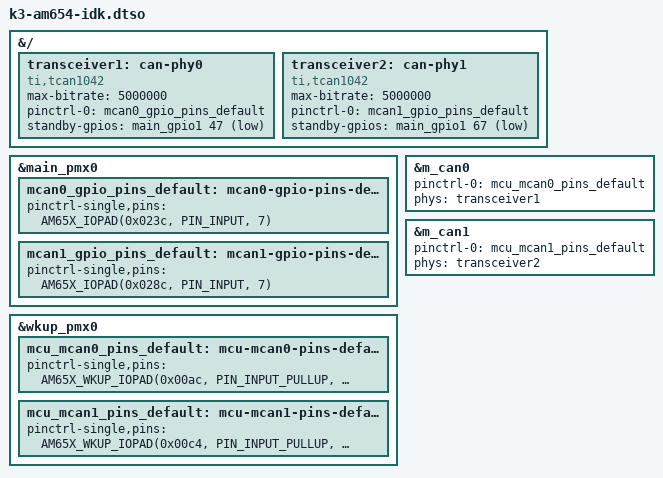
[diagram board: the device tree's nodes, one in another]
// SPDX-License-Identifier: GPL-2.0
/**
 * DT overlay for IDK application board on AM654 EVM
 *
 * Copyright (C) 2018-2023 Texas Instruments Incorporated - https://www.ti.com/
 */

/dts-v1/;
/plugin/;

#include <dt-bindings/gpio/gpio.h>
#include "k3-pinctrl.h"

&{/} {
	transceiver1: can-phy0 {
		compatible = "ti,tcan1042";
		#phy-cells = <0>;
		max-bitrate = <5000000>;
		pinctrl-names = "default";
		pinctrl-0 = <&mcan0_gpio_pins_default>;
		standby-gpios = <&main_gpio1 47 GPIO_ACTIVE_LOW>;
	};

        transceiver2: can-phy1 {
		compatible = "ti,tcan1042";
		#phy-cells = <0>;
		max-bitrate = <5000000>;
		pinctrl-names = "default";
		pinctrl-0 = <&mcan1_gpio_pins_default>;
		standby-gpios = <&main_gpio1 67 GPIO_ACTIVE_LOW>;
	};
};

&main_pmx0 {
	mcan0_gpio_pins_default: mcan0-gpio-pins-default {
		pinctrl-single,pins = <
			AM65X_IOPAD(0x023c, PIN_INPUT, 7) /* (V25) PRG0_PRU0_GPIO18:GPIO1_47 */
		>;
	};

	mcan1_gpio_pins_default: mcan1-gpio-pins-default {
		pinctrl-single,pins = <
			AM65X_IOPAD(0x028c, PIN_INPUT, 7) /* (Y26) PRG0_PRU1_GPIO18.GPIO1_67 */
		>;
	};
};

&wkup_pmx0 {
	mcu_mcan0_pins_default: mcu-mcan0-pins-default {
		pinctrl-single,pins = <
			AM65X_WKUP_IOPAD(0x00ac, PIN_INPUT_PULLUP, 0) /* (W2) MCU_MCAN0_RX */
			AM65X_WKUP_IOPAD(0x00a8, PIN_OUTPUT_PULLUP, 0) /* (W1) MCU_MCAN0_TX */
		>;
	};

	mcu_mcan1_pins_default: mcu-mcan1-pins-default {
		pinctrl-single,pins = <
			AM65X_WKUP_IOPAD(0x00c4, PIN_INPUT_PULLUP, 1) /* (AD3) WKUP_GPIO0_5.MCU_MCAN1_RX */
			AM65X_WKUP_IOPAD(0x00c0, PIN_OUTPUT_PULLUP, 1) /* (AC3) WKUP_GPIO0_4.MCU_MCAN1_TX */
		>;
	};
};

&m_can0 {
	status = "okay";
	pinctrl-names = "default";
	pinctrl-0 = <&mcu_mcan0_pins_default>;
	phys = <&transceiver1>;
};

&m_can1 {
	status = "okay";
	pinctrl-names = "default";
	pinctrl-0 = <&mcu_mcan1_pins_default>;
	phys = <&transceiver2>;
};
